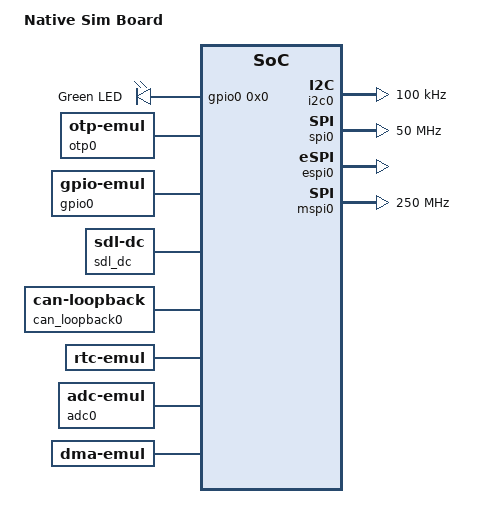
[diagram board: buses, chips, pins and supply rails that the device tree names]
/dts-v1/;

/* node '/' defined in zephyr\dts\common\skeleton.dtsi:9 */
/ {
	#address-cells = < 0x1 >;    /* in zephyr\dts\common\skeleton.dtsi:10 */
	#size-cells = < 0x1 >;       /* in zephyr\dts\common\skeleton.dtsi:11 */
	model = "Native Sim Board";  /* in zephyr\boards\native\native_sim\native_sim.dts:15 */
	compatible = "zephyr,posix"; /* in zephyr\boards\native\native_sim\native_sim.dts:16 */

	/* node '/chosen' defined in zephyr\dts\common\skeleton.dtsi:13 */
	chosen {
		zephyr,console = &uart0;                     /* in zephyr\boards\native\native_sim\native_sim.dts:19 */
		zephyr,shell-uart = &uart0;                  /* in zephyr\boards\native\native_sim\native_sim.dts:20 */
		zephyr,uart-mcumgr = &uart0;                 /* in zephyr\boards\native\native_sim\native_sim.dts:21 */
		zephyr,flash = &flash0;                      /* in zephyr\boards\native\native_sim\native_sim.dts:22 */
		zephyr,entropy = &rng;                       /* in zephyr\boards\native\native_sim\native_sim.dts:23 */
		zephyr,flash-controller = &flashcontroller0; /* in zephyr\boards\native\native_sim\native_sim.dts:24 */
		zephyr,display = &sdl_dc;                    /* in zephyr\boards\native\native_sim\native_sim.dts:25 */
		zephyr,canbus = &can_loopback0;              /* in zephyr\boards\native\native_sim\native_sim.dts:26 */
		zephyr,code-partition = &slot0_partition;    /* in zephyr\boards\native\native_sim\native_sim.dts:27 */
		zephyr,bt-hci = &bt_hci_userchan;            /* in zephyr\boards\native\native_sim\native_sim.dts:28 */
		zephyr,touch = &input_sdl_touch;             /* in zephyr\boards\native\native_sim\native_sim.dts:29 */
	};

	/* node '/aliases' defined in zephyr\dts\common\skeleton.dtsi:15 */
	aliases {
		eeprom-0 = &eeprom0; /* in zephyr\boards\native\native_sim\native_sim.dts:33 */
		i2c-0 = &i2c0;       /* in zephyr\boards\native\native_sim\native_sim.dts:34 */
		spi-0 = &spi0;       /* in zephyr\boards\native\native_sim\native_sim.dts:35 */
		led0 = &led0;        /* in zephyr\boards\native\native_sim\native_sim.dts:36 */
		rtc = &rtc;          /* in zephyr\boards\native\native_sim\native_sim.dts:37 */
	};

	/* node '/leds' defined in zephyr\boards\native\native_sim\native_sim.dts:40 */
	leds: leds {
		compatible = "gpio-leds"; /* in zephyr\boards\native\native_sim\native_sim.dts:41 */

		/* node '/leds/led_0' defined in zephyr\boards\native\native_sim\native_sim.dts:43 */
		led0: led_0 {
			gpios = < &gpio0 0x0 0x0 >; /* in zephyr\boards\native\native_sim\native_sim.dts:44 */
			label = "Green LED";        /* in zephyr\boards\native\native_sim\native_sim.dts:45 */
		};
	};

	/* node '/cpus' defined in zephyr\boards\native\native_sim\native_sim.dts:49 */
	cpus {
		#address-cells = < 0x1 >; /* in zephyr\boards\native\native_sim\native_sim.dts:50 */
		#size-cells = < 0x0 >;    /* in zephyr\boards\native\native_sim\native_sim.dts:51 */

		/* node '/cpus/cpu@0' defined in zephyr\boards\native\native_sim\native_sim.dts:53 */
		cpu0: cpu@0 {
			compatible = "zephyr,native-sim-cpu"; /* in zephyr\boards\native\native_sim\native_sim.dts:54 */
			reg = < 0x0 >;                        /* in zephyr\boards\native\native_sim\native_sim.dts:55 */
		};
	};

	/* node '/flash-controller@0' defined in zephyr\boards\native\native_sim\native_sim.dts:59 */
	flashcontroller0: flash-controller@0 {
		compatible = "zephyr,sim-flash"; /* in zephyr\boards\native\native_sim\native_sim.dts:60 */
		reg = < 0x0 0x200000 >;          /* in zephyr\boards\native\native_sim\native_sim.dts:61 */
		#address-cells = < 0x1 >;        /* in zephyr\boards\native\native_sim\native_sim.dts:63 */
		#size-cells = < 0x1 >;           /* in zephyr\boards\native\native_sim\native_sim.dts:64 */
		erase-value = < 0xff >;          /* in zephyr\boards\native\native_sim\native_sim.dts:65 */

		/* node '/flash-controller@0/flash@0' defined in zephyr\boards\native\native_sim\native_sim.dts:67 */
		flash0: flash@0 {
			status = "okay";               /* in zephyr\boards\native\native_sim\native_sim.dts:68 */
			compatible = "soc-nv-flash";   /* in zephyr\boards\native\native_sim\native_sim.dts:69 */
			erase-block-size = < 0x1000 >; /* in zephyr\boards\native\native_sim\native_sim.dts:70 */
			write-block-size = < 0x1 >;    /* in zephyr\boards\native\native_sim\native_sim.dts:71 */
			reg = < 0x0 0x200000 >;        /* in zephyr\boards\native\native_sim\native_sim.dts:72 */

			/* node '/flash-controller@0/flash@0/partitions' defined in zephyr\boards\native\native_sim\native_sim.dts:74 */
			partitions {
				compatible = "fixed-partitions"; /* in zephyr\boards\native\native_sim\native_sim.dts:75 */
				#address-cells = < 0x1 >;        /* in zephyr\boards\native\native_sim\native_sim.dts:76 */
				#size-cells = < 0x1 >;           /* in zephyr\boards\native\native_sim\native_sim.dts:77 */

				/* node '/flash-controller@0/flash@0/partitions/partition@0' defined in zephyr\boards\native\native_sim\native_sim.dts:79 */
				boot_partition: partition@0 {
					label = "mcuboot";    /* in zephyr\boards\native\native_sim\native_sim.dts:80 */
					reg = < 0x0 0xc000 >; /* in zephyr\boards\native\native_sim\native_sim.dts:81 */
				};

				/* node '/flash-controller@0/flash@0/partitions/partition@c000' defined in zephyr\boards\native\native_sim\native_sim.dts:84 */
				slot0_partition: partition@c000 {
					label = "image-0";        /* in zephyr\boards\native\native_sim\native_sim.dts:85 */
					reg = < 0xc000 0x69000 >; /* in zephyr\boards\native\native_sim\native_sim.dts:86 */
				};

				/* node '/flash-controller@0/flash@0/partitions/partition@75000' defined in zephyr\boards\native\native_sim\native_sim.dts:89 */
				slot1_partition: partition@75000 {
					label = "image-1";         /* in zephyr\boards\native\native_sim\native_sim.dts:90 */
					reg = < 0x75000 0x69000 >; /* in zephyr\boards\native\native_sim\native_sim.dts:91 */
				};

				/* node '/flash-controller@0/flash@0/partitions/partition@de000' defined in zephyr\boards\native\native_sim\native_sim.dts:94 */
				scratch_partition: partition@de000 {
					label = "image-scratch";   /* in zephyr\boards\native\native_sim\native_sim.dts:95 */
					reg = < 0xde000 0x1e000 >; /* in zephyr\boards\native\native_sim\native_sim.dts:96 */
				};

				/* node '/flash-controller@0/flash@0/partitions/partition@fc000' defined in zephyr\boards\native\native_sim\native_sim.dts:99 */
				storage_partition: partition@fc000 {
					label = "storage";        /* in zephyr\boards\native\native_sim\native_sim.dts:100 */
					reg = < 0xfc000 0x4000 >; /* in zephyr\boards\native\native_sim\native_sim.dts:101 */
				};
			};
		};
	};

	/* node '/eeprom' defined in zephyr\boards\native\native_sim\native_sim.dts:107 */
	eeprom0: eeprom {
		status = "okay";                  /* in zephyr\boards\native\native_sim\native_sim.dts:108 */
		compatible = "zephyr,sim-eeprom"; /* in zephyr\boards\native\native_sim\native_sim.dts:109 */
		size = < 0x8000 >;                /* in zephyr\boards\native\native_sim\native_sim.dts:110 */
	};

	/* node '/otp' defined in zephyr\boards\native\native_sim\native_sim.dts:113 */
	otp0: otp {
		compatible = "zephyr,otp-emul"; /* in zephyr\boards\native\native_sim\native_sim.dts:114 */
		size = < 0x400 >;               /* in zephyr\boards\native\native_sim\native_sim.dts:115 */
		status = "okay";                /* in zephyr\boards\native\native_sim\native_sim.dts:116 */
	};

	/* node '/i2c@100' defined in zephyr\boards\native\native_sim\native_sim.dts:119 */
	i2c0: i2c@100 {
		status = "okay";                           /* in zephyr\boards\native\native_sim\native_sim.dts:120 */
		compatible = "zephyr,i2c-emul-controller"; /* in zephyr\boards\native\native_sim\native_sim.dts:121 */
		clock-frequency = < 0x186a0 >;             /* in zephyr\boards\native\native_sim\native_sim.dts:122 */
		#address-cells = < 0x1 >;                  /* in zephyr\boards\native\native_sim\native_sim.dts:123 */
		#size-cells = < 0x0 >;                     /* in zephyr\boards\native\native_sim\native_sim.dts:124 */
		#forward-cells = < 0x1 >;                  /* in zephyr\boards\native\native_sim\native_sim.dts:125 */
		reg = < 0x100 0x4 >;                       /* in zephyr\boards\native\native_sim\native_sim.dts:126 */
	};

	/* node '/spi@200' defined in zephyr\boards\native\native_sim\native_sim.dts:129 */
	spi0: spi@200 {
		status = "okay";                           /* in zephyr\boards\native\native_sim\native_sim.dts:130 */
		compatible = "zephyr,spi-emul-controller"; /* in zephyr\boards\native\native_sim\native_sim.dts:131 */
		clock-frequency = < 0x2faf080 >;           /* in zephyr\boards\native\native_sim\native_sim.dts:132 */
		#address-cells = < 0x1 >;                  /* in zephyr\boards\native\native_sim\native_sim.dts:133 */
		#size-cells = < 0x0 >;                     /* in zephyr\boards\native\native_sim\native_sim.dts:134 */
		reg = < 0x200 0x4 >;                       /* in zephyr\boards\native\native_sim\native_sim.dts:135 */
	};

	/* node '/espi@300' defined in zephyr\boards\native\native_sim\native_sim.dts:138 */
	espi0: espi@300 {
		status = "okay";                            /* in zephyr\boards\native\native_sim\native_sim.dts:139 */
		compatible = "zephyr,espi-emul-controller"; /* in zephyr\boards\native\native_sim\native_sim.dts:140 */
		reg = < 0x300 0x4 >;                        /* in zephyr\boards\native\native_sim\native_sim.dts:141 */
		#address-cells = < 0x1 >;                   /* in zephyr\boards\native\native_sim\native_sim.dts:142 */
		#size-cells = < 0x0 >;                      /* in zephyr\boards\native\native_sim\native_sim.dts:143 */
	};

	/* node '/mspi@400' defined in zephyr\boards\native\native_sim\native_sim.dts:146 */
	mspi0: mspi@400 {
		status = "okay";                            /* in zephyr\boards\native\native_sim\native_sim.dts:147 */
		compatible = "zephyr,mspi-emul-controller"; /* in zephyr\boards\native\native_sim\native_sim.dts:148 */
		clock-frequency = < 0xee6b280 >;            /* in zephyr\boards\native\native_sim\native_sim.dts:149 */
		reg = < 0x400 0x4 >;                        /* in zephyr\boards\native\native_sim\native_sim.dts:150 */
		#address-cells = < 0x1 >;                   /* in zephyr\boards\native\native_sim\native_sim.dts:151 */
		#size-cells = < 0x0 >;                      /* in zephyr\boards\native\native_sim\native_sim.dts:152 */
	};

	/* node '/uart' defined in zephyr\boards\native\native_sim\native_sim.dts:155 */
	uart0: uart {
		status = "okay";                       /* in zephyr\boards\native\native_sim\native_sim.dts:156 */
		compatible = "zephyr,native-pty-uart"; /* in zephyr\boards\native\native_sim\native_sim.dts:157 */
		current-speed = < 0x0 >;               /* in zephyr\boards\native\native_sim\native_sim.dts:161 */
	};

	/* node '/uart_1' defined in zephyr\boards\native\native_sim\native_sim.dts:164 */
	uart1: uart_1 {
		status = "disabled";                   /* in zephyr\boards\native\native_sim\native_sim.dts:165 */
		compatible = "zephyr,native-pty-uart"; /* in zephyr\boards\native\native_sim\native_sim.dts:166 */
		current-speed = < 0x0 >;               /* in zephyr\boards\native\native_sim\native_sim.dts:170 */
	};

	/* node '/rng' defined in zephyr\boards\native\native_sim\native_sim.dts:173 */
	rng: rng {
		status = "okay";                      /* in zephyr\boards\native\native_sim\native_sim.dts:174 */
		compatible = "zephyr,native-sim-rng"; /* in zephyr\boards\native\native_sim\native_sim.dts:175 */
	};

	/* node '/counter' defined in zephyr\boards\native\native_sim\native_sim.dts:178 */
	counter0: counter {
		status = "okay";                          /* in zephyr\boards\native\native_sim\native_sim.dts:179 */
		compatible = "zephyr,native-sim-counter"; /* in zephyr\boards\native\native_sim\native_sim.dts:180 */
	};

	/* node '/gpio_emul' defined in zephyr\boards\native\native_sim\native_sim.dts:183 */
	gpio0: gpio_emul {
		status = "okay";                 /* in zephyr\boards\native\native_sim\native_sim.dts:184 */
		compatible = "zephyr,gpio-emul"; /* in zephyr\boards\native\native_sim\native_sim.dts:185 */
		rising-edge;                     /* in zephyr\boards\native\native_sim\native_sim.dts:186 */
		falling-edge;                    /* in zephyr\boards\native\native_sim\native_sim.dts:187 */
		high-level;                      /* in zephyr\boards\native\native_sim\native_sim.dts:188 */
		low-level;                       /* in zephyr\boards\native\native_sim\native_sim.dts:189 */
		gpio-controller;                 /* in zephyr\boards\native\native_sim\native_sim.dts:190 */
		#gpio-cells = < 0x2 >;           /* in zephyr\boards\native\native_sim\native_sim.dts:191 */
		phandle = < 0x1 >;               /* in zephyr\boards\native\native_sim\native_sim.dts:44 */
	};

	/* node '/udc0' defined in zephyr\boards\native\native_sim\native_sim.dts:194 */
	zephyr_udc0: udc0 {
		compatible = "zephyr,native-posix-udc"; /* in zephyr\boards\native\native_sim\native_sim.dts:195 */
	};

	/* node '/sdl_dc' defined in zephyr\boards\native\native_sim\native_sim.dts:198 */
	sdl_dc: sdl_dc {
		compatible = "zephyr,sdl-dc"; /* in zephyr\boards\native\native_sim\native_sim.dts:199 */
		pixel-format = < 0x8 >;       /* in zephyr\boards\native\native_sim\native_sim.dts:200 */
		height = < 0xf0 >;            /* in zephyr\boards\native\native_sim\native_sim.dts:201 */
		width = < 0x140 >;            /* in zephyr\boards\native\native_sim\native_sim.dts:202 */
		phandle = < 0x2 >;            /* in zephyr\boards\native\native_sim\native_sim.dts:207 */
	};

	/* node '/input-sdl-touch' defined in zephyr\boards\native\native_sim\native_sim.dts:205 */
	input_sdl_touch: input-sdl-touch {
		compatible = "zephyr,input-sdl-touch"; /* in zephyr\boards\native\native_sim\native_sim.dts:206 */
		display = < &sdl_dc >;                 /* in zephyr\boards\native\native_sim\native_sim.dts:207 */
	};

	/* node '/can_loopback0' defined in zephyr\boards\native\native_sim\native_sim.dts:210 */
	can_loopback0: can_loopback0 {
		status = "okay";                    /* in zephyr\boards\native\native_sim\native_sim.dts:211 */
		compatible = "zephyr,can-loopback"; /* in zephyr\boards\native\native_sim\native_sim.dts:212 */
	};

	/* node '/can' defined in zephyr\boards\native\native_sim\native_sim.dts:215 */
	can0: can {
		status = "disabled";                    /* in zephyr\boards\native\native_sim\native_sim.dts:216 */
		compatible = "zephyr,native-linux-can"; /* in zephyr\boards\native\native_sim\native_sim.dts:217 */
		host-interface = "zcan0";               /* in zephyr\boards\native\native_sim\native_sim.dts:221 */
	};

	/* node '/rtc' defined in zephyr\boards\native\native_sim\native_sim.dts:224 */
	rtc: rtc {
		status = "okay";                /* in zephyr\boards\native\native_sim\native_sim.dts:225 */
		compatible = "zephyr,rtc-emul"; /* in zephyr\boards\native\native_sim\native_sim.dts:226 */
		alarms-count = < 0x2 >;         /* in zephyr\boards\native\native_sim\native_sim.dts:227 */
	};

	/* node '/adc' defined in zephyr\boards\native\native_sim\native_sim.dts:230 */
	adc0: adc {
		compatible = "zephyr,adc-emul"; /* in zephyr\boards\native\native_sim\native_sim.dts:231 */
		nchannels = < 0x2 >;            /* in zephyr\boards\native\native_sim\native_sim.dts:232 */
		#io-channel-cells = < 0x1 >;    /* in zephyr\boards\native\native_sim\native_sim.dts:233 */
		status = "okay";                /* in zephyr\boards\native\native_sim\native_sim.dts:234 */
	};

	/* node '/dma' defined in zephyr\boards\native\native_sim\native_sim.dts:237 */
	dma: dma {
		compatible = "zephyr,dma-emul"; /* in zephyr\boards\native\native_sim\native_sim.dts:238 */
		#dma-cells = < 0x1 >;           /* in zephyr\boards\native\native_sim\native_sim.dts:239 */
		stack-size = < 0x1000 >;        /* in zephyr\boards\native\native_sim\native_sim.dts:240 */
	};

	/* node '/bt_hci_userchan' defined in zephyr\boards\native\native_sim\native_sim.dts:243 */
	bt_hci_userchan: bt_hci_userchan {
		compatible = "zephyr,bt-hci-userchan"; /* in zephyr\boards\native\native_sim\native_sim.dts:244 */
		status = "okay";                       /* in zephyr\boards\native\native_sim\native_sim.dts:245 */
	};

	/* node '/performance-states' defined in zephyr\boards\native\native_sim\native_sim.dts:248 */
	performance-states {

		/* node '/performance-states/pstate_0' defined in zephyr\boards\native\native_sim\native_sim.dts:249 */
		pstate_0: pstate_0 {
			compatible = "zephyr,native-sim-pstate"; /* in zephyr\boards\native\native_sim\native_sim.dts:250 */
			load-threshold = < 0x32 >;               /* in zephyr\boards\native\native_sim\native_sim.dts:251 */
			pstate-id = < 0x0 >;                     /* in zephyr\boards\native\native_sim\native_sim.dts:252 */
		};

		/* node '/performance-states/pstate_1' defined in zephyr\boards\native\native_sim\native_sim.dts:255 */
		pstate_1: pstate_1 {
			compatible = "zephyr,native-sim-pstate"; /* in zephyr\boards\native\native_sim\native_sim.dts:256 */
			load-threshold = < 0x14 >;               /* in zephyr\boards\native\native_sim\native_sim.dts:257 */
			pstate-id = < 0x1 >;                     /* in zephyr\boards\native\native_sim\native_sim.dts:258 */
		};

		/* node '/performance-states/pstate_2' defined in zephyr\boards\native\native_sim\native_sim.dts:261 */
		pstate_2: pstate_2 {
			compatible = "zephyr,native-sim-pstate"; /* in zephyr\boards\native\native_sim\native_sim.dts:262 */
			load-threshold = < 0x0 >;                /* in zephyr\boards\native\native_sim\native_sim.dts:263 */
			pstate-id = < 0x2 >;                     /* in zephyr\boards\native\native_sim\native_sim.dts:264 */
		};
	};

	/* node '/ptp_clock' defined in zephyr\boards\native\native_sim\native_sim.dts:268 */
	ptp_clock: ptp_clock {
		compatible = "zephyr,native-ptp-clock"; /* in zephyr\boards\native\native_sim\native_sim.dts:269 */
		status = "okay";                        /* in zephyr\boards\native\native_sim\native_sim.dts:270 */
	};
};
